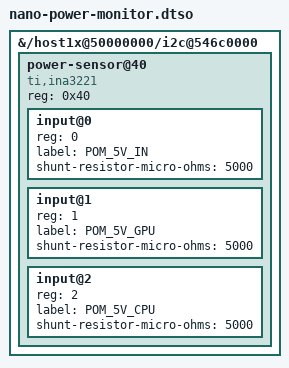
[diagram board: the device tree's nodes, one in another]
// SPDX-License-Identifier: GPL-2.0-only
/dts-v1/;
/plugin/;

/* NVIDIA's BSP swaps input and GPU channels for P3448 SKU 0000 FAB 100+. */
&{/host1x@50000000/i2c@546c0000} {
	#address-cells = <1>;
	#size-cells = <0>;

	power-sensor@40 {
		compatible = "ti,ina3221";
		reg = <0x40>;
		#address-cells = <1>;
		#size-cells = <0>;

		input@0 {
			reg = <0>;
			label = "POM_5V_IN";
			shunt-resistor-micro-ohms = <5000>;
		};

		input@1 {
			reg = <1>;
			label = "POM_5V_GPU";
			shunt-resistor-micro-ohms = <5000>;
		};

		input@2 {
			reg = <2>;
			label = "POM_5V_CPU";
			shunt-resistor-micro-ohms = <5000>;
		};
	};
};
